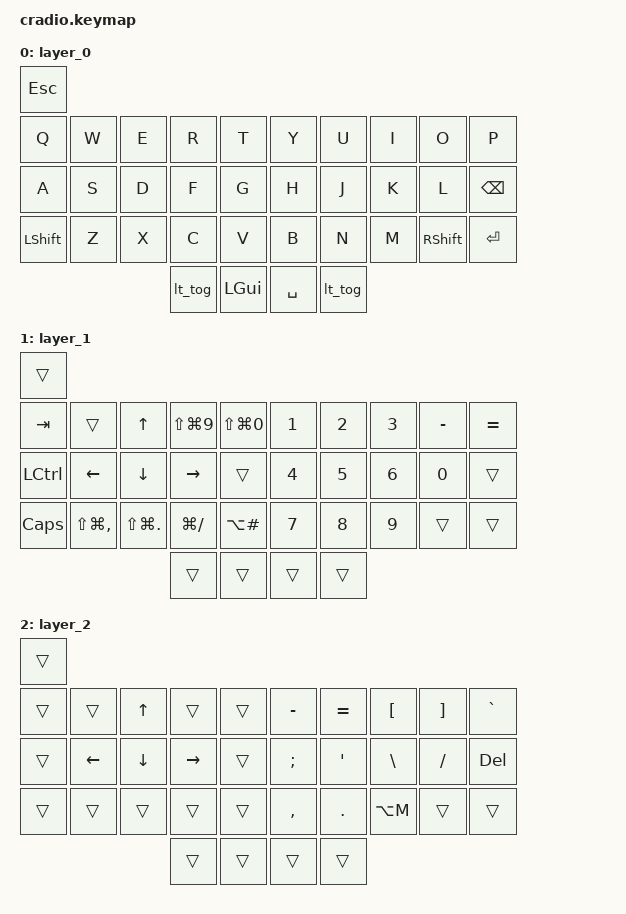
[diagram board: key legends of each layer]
#include <behaviors.dtsi>
#include <dt-bindings/zmk/keys.h>

/ {
    behaviors {
        lt_tog: layer_tap_toggle_1 {
            compatible = "zmk,behavior-hold-tap";
            label = "LT_TOG_1";
            #binding-cells = <0>;
            flavor = "tap-preferred";
            tapping-term-ms = <200>;
            bindings = <&tog 1>, <&mo 1>;
        };
    };
};

/ {
    keymap {
        compatible = "zmk,keymap";

        layer_0 {
            bindings = <
&kp ESC
&kp Q      &kp W  &kp E  &kp R        &kp T       &kp Y      &kp U        &kp I  &kp O      &kp P
&kp A      &kp S  &kp D  &kp F        &kp G       &kp H      &kp J        &kp K  &kp L      &kp BSPC
&kp LSHFT  &kp Z  &kp X  &kp C        &kp V       &kp B      &kp N        &kp M  &kp RSHFT  &kp ENTER
                         &lt_tog 1 1  &kp LGUI    &kp SPACE  &lt_tog 2 2
            >;
        };

        layer_1 {
            bindings = <
&trans
&kp TAB    &trans             &kp UP           &kp LS(LG(N9))  &kp LS(LG(N0))    &kp N1  &kp N2  &kp N3  &kp MINUS  &kp EQUAL
&kp LCTRL  &kp LEFT           &kp DOWN         &kp RIGHT       &trans            &kp N4  &kp N5  &kp N6  &kp N0     &trans
&kp CAPS   &kp LS(LG(COMMA))  &kp LS(LG(DOT))  &kp LG(FSLH)    &kp LA(POUND)     &kp N7  &kp N8  &kp N9  &trans     &trans
                                               &trans          &trans            &trans  &trans
            >;
        };

        layer_2 {
            bindings = <
&trans
&trans  &trans    &kp UP    &trans     &trans    &kp MINUS  &kp EQUAL  &kp LBKT   &kp RBKT  &kp GRAVE
&trans  &kp LEFT  &kp DOWN  &kp RIGHT  &trans    &kp SEMI   &kp SQT    &kp BSLH   &kp FSLH  &kp DEL
&trans  &trans    &trans    &trans     &trans    &kp COMMA  &kp DOT    &kp LA(M)  &trans    &trans
                            &trans     &trans    &trans     &trans
            >;
        };
    };
};
